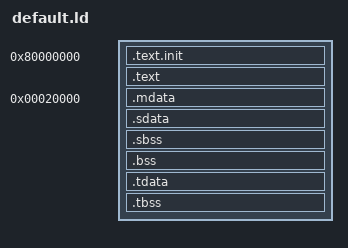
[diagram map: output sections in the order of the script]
/*======================================================================*/
/* Proxy kernel linker script                                           */
/*======================================================================*/
/* This is the linker script used when building the proxy kernel. */

/*----------------------------------------------------------------------*/
/* Setup                                                                */
/*----------------------------------------------------------------------*/

/* The OUTPUT_ARCH command specifies the machine architecture where the
   argument is one of the names used in the BFD library. More
   specifically one of the entires in bfd/cpu-mips.c */

OUTPUT_ARCH( "riscv" )
ENTRY(_start)

/*----------------------------------------------------------------------*/
/* Sections                                                             */
/*----------------------------------------------------------------------*/

SECTIONS
{

  /* text: test code section */
  . = 0x80000000;
  .text.init : { *(.text.init) }
  .text : { *(.text) _etext = . ; }
  .mdata 0x20000:
    { _data = . ; *(.data); _edata = . ;  }
  .sdata : {
    __global_pointer$ = . + 0x800;
    *(.srodata.cst16) *(.srodata.cst8) *(.srodata.cst4) *(.srodata.cst2) *(.srodata*)
    *(.sdata .sdata.* .gnu.linkonce.s.*)
  }
  .sbss : {
    *(.sbss .sbss.* .gnu.linkonce.sb.*)
    *(.scommon)
  }
   .bss :
    { _bstart = . ;  *(.bss) *(COMMON) ; _bend = . ;}

  .tdata :
  {
    _tls_data = .;
    *(.tdata.begin)
    *(.tdata)
    *(.tdata.end)
  }
  .tbss :
  {
    *(.tbss)
    *(.tbss.end)
  }

  /* End of uninitalized data segement */
  _end = .;
}

